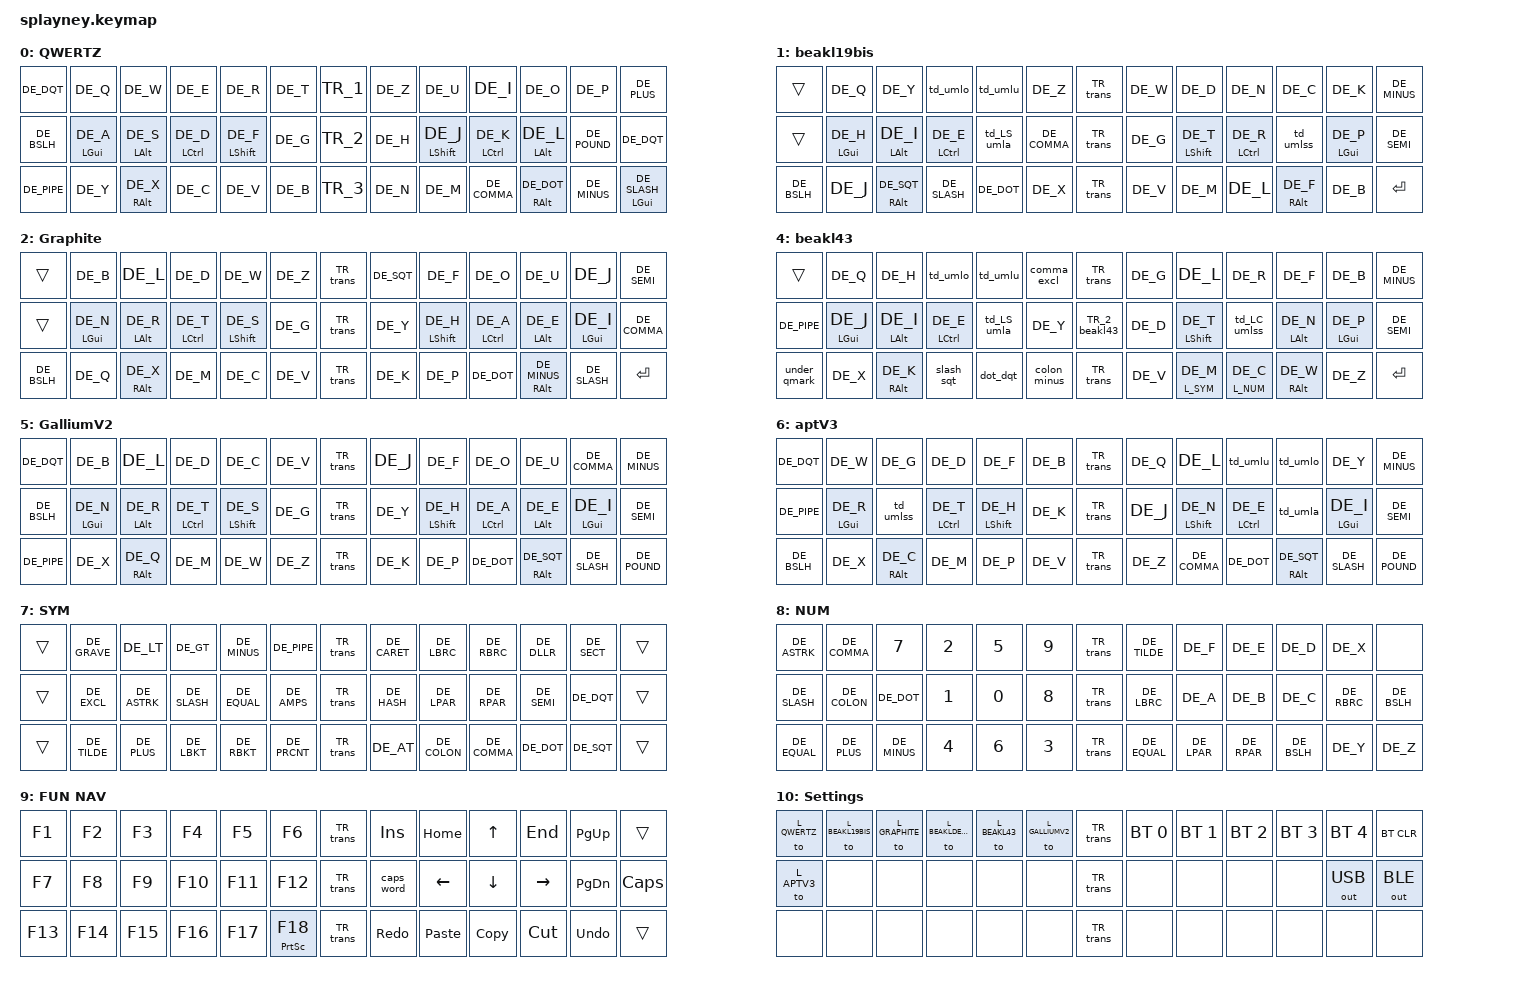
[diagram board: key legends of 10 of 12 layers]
/*
 * Copyright (c) 2023 The ZMK Contributors
 *
 * SPDX-License-Identifier: MIT
 */

#include <behaviors.dtsi>
#include <dt-bindings/zmk/bt.h>
#include <dt-bindings/zmk/keys.h>
#include <dt-bindings/zmk/outputs.h>

#define ZMK_POINTING_DEFAULT_MOVE_VAL 1500  // default: 600
#define ZMK_POINTING_DEFAULT_SCRL_VAL 100    // default: 10
#include <dt-bindings/zmk/pointing.h>

#include <locale/keys_de.h>
#include <locale/keys_us_international.h>

#define L_QWERTZ 0
#define L_BEAKL19BIS 1
#define L_GRAPHITE 2
#define L_BEAKLDETECH 3
#define L_BEAKL43 4
#define L_GALLIUMV2 5
#define L_APTV3 6

#define L_SYM 7
#define L_NUM 8
#define L_FUNNAV 9
#define L_SETTINGS 10
#define L_MEDIAMAUS 11

#define Undo   LC(Z)
#define Cut    LC(X)
#define Copy   LC(C)
#define Paste  LC(V)
#define Redo   LC(Y)

#include "combos.dtsi"

/*
            7.2 7.3     8.3 8.2
 6.1 6.2 6.3 7.1             8.1 9.3 9.2 9.1
*/

/*              Col 6                   7                         8                         9       */
#define TR_1    &lt L_NUM ESC           &lt L_MEDIAMAUS ENTER     &lt L_MEDIAMAUS ENTER     &lt L_NUM ESC  
#define TR_2    &lt L_SYM BSPC          &none                     &none                     &lt L_SYM DELETE
#define TR_3    &lt L_FUNNAV DE_SPACE   &mo L_SETTINGS            &mo L_SETTINGS            &lt L_FUNNAV DE_SPACE

#define TR_2_beakl43    &lt L_SYM BSPC          &bslh_pipe             &none                     &lt L_SYM DELETE

/*   │ SYM │ BSPC│SPACE│ENTER│   │ENTER│SPACE│DEL  │ NAV │ */
/*               Col 6          7                8               9       */
/*#define TR_B1    &mo L_SYM      &kp ENTER        &kp ENTER       &mo L_NUM   
#define TR_B2    &kp BSPC       &blsh_pipe       &none           &kp DELETE
#define TR_B3    &kp DE_SPACE   &mo L_SETTINGS   &mo L_SETTINGS  &kp DE_SPACE
*/
// #define TR_20   &lt L_SYMNUM DE_ESC    &none                     &mo L_NAV         &lt L_FUN DELETE 


#define TR_trans &trans &trans &trans &trans
#define TR_half_trans &trans &trans 


/*
#define TR_1 &kp DE_A &kp DE_B &kp DE_C &kp DE_D
#define TR_2 &kp DE_E &kp DE_F &kp DE_G &kp DE_H
#define TR_3 &kp DE_I &kp DE_J &kp DE_K &kp DE_L
*/


&mmv {
    acceleration-exponent = <1>;          // 1
    time-to-max-speed-ms = <1500>;         // 300
    delay-ms = <0>;                       // 0
};

&msc {
    acceleration-exponent = <0>;          // 0
    time-to-max-speed-ms = <5000>;         // 300
    delay-ms = <0>;                       // 0
};



/ {
    behaviors {

/* HOME ROW MODS */
        thm: homerow_mods {
            compatible = "zmk,behavior-hold-tap";
            #binding-cells = <2>;
            tapping-term-ms = <150>;
            quick-tap-ms = <0>;
            flavor = "tap-preferred";
            bindings = <&kp>, <&kp>;
        }; 
        hm: balanced_homerow_mods {
            compatible = "zmk,behavior-hold-tap";
            #binding-cells = <2>;
            tapping-term-ms = <400>;    // <---[[moderate duration]]
            quick-tap-ms = <0>;
            flavor = "tap-preferred";
            bindings = <&kp>, <&kp>;
        };

        // Ctrl, GUI (sehr bewusst)
        hm_strict: hmr_strict {
            compatible = "zmk,behavior-hold-tap";
            #binding-cells = <2>;
            flavor = "tap-preferred";
            tapping-term-ms = <260>;
            require-prior-idle-ms = <170>;
            quick-tap-ms = <120>;
            hold-trigger-on-release;
            bindings = <&kp>, <&kp>;
        };

        // Alt / RAlt (mittel)
        hm_mid: hmr_mid {
            compatible = "zmk,behavior-hold-tap";
            #binding-cells = <2>;
            flavor = "tap-preferred";
            tapping-term-ms = <240>;
            require-prior-idle-ms = <140>;
            quick-tap-ms = <120>;
            hold-trigger-on-release;
            bindings = <&kp>, <&kp>;
        };

        // Shift (am schnellsten)
        hm_shift: hmr_shift {
            compatible = "zmk,behavior-hold-tap";
            #binding-cells = <2>;
            flavor = "tap-preferred";
            tapping-term-ms = <210>;
            require-prior-idle-ms = <120>;
            quick-tap-ms = <110>;
            bindings = <&kp>, <&kp>;
         };
//            hold-trigger-on-release;


/*---------------------*/
     /*       
        mac_caps: mac_caps {
          compatible = "zmk,behavior-macro";
          #binding-cells = <0>;
          tap-ms = <100>;
          bindings = <&kp CAPS>;
        };
            
        tab_caps: tab_caps {
          compatible = "zmk,behavior-hold-tap";
          label = "TAB_CAPS";
          #binding-cells = <0>;
          tapping-term-ms = <200>;
          flavor = "tap-preferred";
          bindings = <&mac_caps>, <&kp TAB>;
        };
     */

        td_umla: tap_dance_generic_a {
            compatible = "zmk,behavior-tap-dance";
            #binding-cells = <0>;
            tapping-term-ms = <200>;
            bindings = <&mt LALT DE_A>, <&kp DE_A_UMLAUT>;
        };
/*
        td_LS_umla: tap_dance_generic_LS_a {
            compatible = "zmk,behavior-tap-dance";
            #binding-cells = <0>;
            tapping-term-ms = <200>;
            bindings = <&mt LSHIFT DE_A>, <&kp DE_A_UMLAUT>;
        };
*/
        td_LS_umla: tap_dance_generic_LS_a {
            compatible = "zmk,behavior-tap-dance";
            #binding-cells = <0>;
            tapping-term-ms = <210>;             // wie hm_shift
            // quick-tap-ms = <110>;                // schützt Doppeltaps
            // flavor = "tap-preferred";            // Tap first
            // hold-trigger-on-release;             // Hold wird erst beim Loslassen entschieden
            bindings = <&mt LSHIFT DE_A>, <&kp DE_A_UMLAUT>;
        };

        td_umlo: tap_dance_generic_o {
            compatible = "zmk,behavior-tap-dance";
            #binding-cells = <0>;
            tapping-term-ms = <200>;
            bindings = <&kp DE_O>, <&kp DE_O_UMLAUT>;
        };
        td_umlu: tap_dance_generic_u {
            compatible = "zmk,behavior-tap-dance";
            #binding-cells = <0>;
            tapping-term-ms = <200>;
            bindings = <&kp DE_U>, <&kp DE_U_UMLAUT>;
        };
        td_umlss: tap_dance_generic_LC_ss {
            compatible = "zmk,behavior-tap-dance";
            #binding-cells = <0>;
            tapping-term-ms = <200>;
            bindings = <&mt LALT DE_S>, <&kp DE_SHARP_S>;
        };
/*
        td_LC_umlss: tap_dance_generic_ss {
            compatible = "zmk,behavior-tap-dance";
            #binding-cells = <0>;
            tapping-term-ms = <200>;
            bindings = <&mt LCTRL DE_S>, <&kp DE_SHARP_S>;
        };
*/
        td_LC_umlss: tap_dance_generic_ss {
            compatible = "zmk,behavior-tap-dance";
            #binding-cells = <0>;
            // tapping-term-ms = <260>;          // wie hm_strict für Ctrl
            // quick-tap-ms = <120>;             // schützt Doppeltaps
            // flavor = "tap-preferred";         // Tap first
            // hold-trigger-on-release;          // Hold wird erst beim Loslassen entschieden
            bindings = <&mt LCTRL DE_S>, <&kp DE_SHARP_S>;
         };

        // BEAKL43
        comma_excl: comma_excl {
            compatible = "zmk,behavior-mod-morph";
            #binding-cells = <0>;
            // Das erste Binding ist für den unmodifizierten Zustand (ohne Shift)
            // Das zweite Binding ist für den modifizierten Zustand (mit Shift)
            bindings = <&kp DE_COMMA>, <&kp DE_EXCLAMATION>; 
            // Die Modifikatoren, die das Verhalten ändern sollen (linker oder rechter Shift)
            mods = <(MOD_LSFT | MOD_RSFT)>; 
        };
        quote_under: quote_under {
            compatible = "zmk,behavior-mod-morph";
            #binding-cells = <0>;
            bindings = <&kp DE_DQT>, <&kp DE_UNDERSCORE>;
            mods = <(MOD_LSFT | MOD_RSFT)>;
        };
        dot_grave: dot_grave {
            compatible = "zmk,behavior-mod-morph";
            #binding-cells = <0>;
            bindings = <&kp DE_DOT>, <&kp DE_GRAVE>;
            mods = <(MOD_LSFT | MOD_RSFT)>;
        };
        sq_qmark: sq_qmark {
            compatible = "zmk,behavior-mod-morph";
            #binding-cells = <0>;
            bindings = <&kp DE_SQT>, <&kp DE_QMARK>;
            mods = <(MOD_LSFT | MOD_RSFT)>;
        };
        slash_sqt: slash_sqt {
            compatible = "zmk,behavior-mod-morph";
            #binding-cells = <0>;
            bindings = <&kp DE_SLASH>, <&kp DE_SQT>;
            mods = <(MOD_LSFT | MOD_RSFT)>;
        };
        dot_dqt: dot_dqt {
            compatible = "zmk,behavior-mod-morph";
            #binding-cells = <0>;
            bindings = <&kp DE_DOT>, <&kp DE_DQT>;
            mods = <(MOD_LSFT | MOD_RSFT)>;
        };
        colon_minus: colon_minus {
            compatible = "zmk,behavior-mod-morph";
            #binding-cells = <0>;
            bindings = <&kp DE_COLON>, <&kp DE_MINUS>;
            mods = <(MOD_LSFT | MOD_RSFT)>;
            keep-mods = <0>;
        };
        bslh_pipe: bslh_pipe {
            compatible = "zmk,behavior-mod-morph";
            #binding-cells = <0>;
            bindings = <&kp DE_BSLH>, <&kp DE_PIPE>;
            mods = <(MOD_LSFT | MOD_RSFT)>;
        };
        under_qmark: under_qmark {
            compatible = "zmk,behavior-mod-morph";
            #binding-cells = <0>;
            bindings = <&kp DE_UNDER>, <&kp DE_QMARK>;
            mods = <(MOD_LSFT | MOD_RSFT)>;
        };

        semicolon_backtick: semicolon_backtick {
            compatible = "zmk,behavior-mod-morph";
            #binding-cells = <0>;
            // Normal: ; , Shift: `
            bindings = <&kp DE_SEMI>, <&kp DE_GRAVE>; 
            mods = <(MOD_LSFT | MOD_RSFT)>; 
        };

        hash_tilde: hash_tilde {
            compatible = "zmk,behavior-mod-morph";
            #binding-cells = <0>;
            // Normal: # , Shift: ~
            bindings = <&kp DE_HASH>, <&kp DE_TILDE>; 
            mods = <(MOD_LSFT | MOD_RSFT)>; 
        };

        equal_caret: equal_caret {
            compatible = "zmk,behavior-mod-morph";
            #binding-cells = <0>;
            // Normal: = , Shift: ^
            bindings = <&kp DE_EQUAL>, <&kp DE_CARET>; 
            mods = <(MOD_LSFT | MOD_RSFT)>; 
        };

        asterisk_plus: asterisk_plus {
            compatible = "zmk,behavior-mod-morph";
            #binding-cells = <0>;
            // Normal: * , Shift: +
            bindings = <&kp DE_ASTRK>, <&kp DE_PLUS>; 
            mods = <(MOD_LSFT | MOD_RSFT)>; 
        };


        // layer_quote_under: layer_quote_under {
        //     compatible = "zmk,behavior-hold-tap";
        //     // #binding-cells = <3>; // Tap-Binding und Hold-Binding
        //     tapping-term-ms = <400>; // Nutzt den gleichen tapping-term wie hm
        //     quick-tap-ms = <0>;
        //     flavor = "tap-preferred"; // Bevorzugt Tap, wie deine anderen HRMs
        //     // Binding 1 (Tap): Dein bestehendes mod-morph Behavior
        //     // Binding 2 (Hold): Layer-Wechsel zur gewünschten Symbol-Layer (hier ein Platzhalter, z.B. SYMBOL_LAYER)
        //     bindings = <&quote_under &mo 7>; // L_SYM Hier ist das erste Binding dein mod-morph
        // };

        // layer_dot_grave: layer_dot_grave {
        //     compatible = "zmk,behavior-hold-tap";
        //     // #binding-cells = <3>; // Tap-Binding und Hold-Binding
        //     tapping-term-ms = <400>; // Nutzt den gleichen tapping-term wie hm
        //     quick-tap-ms = <0>;
        //     flavor = "tap-preferred"; // Bevorzugt Tap, wie deine anderen HRMs
        //     // Binding 1 (Tap): Dein bestehendes mod-morph Behavior
        //     // Binding 2 (Hold): Layer-Wechsel zur gewünschten Numpad-Layer (hier ein Platzhalter, z.B. NUMPAD_LAYER)
        //     bindings = <&dot_grave &mo 8>; // L_NUM Hier ist das erste Binding dein mod-morph
        // };
    };

    keymap {
        compatible = "zmk,keymap";

        default_layer {
            bindings = <
                &kp DE_DQT   &kp DE_Q      &kp DE_W       &kp DE_E        &kp DE_R         &kp DE_T      TR_1    &kp DE_Z  &kp DE_U        &kp DE_I          &kp DE_O        &kp DE_P           &kp DE_PLUS
                &kp DE_BSLH  &hm LGUI DE_A &hm LALT DE_S  &hm LCTRL DE_D  &hm LSHIFT DE_F  &kp DE_G      TR_2    &kp DE_H  &hm LSHIFT DE_J &hm LCTRL DE_K    &hm LALT DE_L   &kp DE_POUND       &kp DE_DQT
                &kp DE_PIPE  &kp DE_Y      &hm RALT DE_X  &kp DE_C        &kp DE_V         &kp DE_B      TR_3    &kp DE_N  &kp DE_M        &kp DE_COMMA      &hm RALT DE_DOT &kp DE_MINUS       &hm LGUI DE_SLASH
            >;
            label = "QWERTZ";
        };

        // beakl19bis
        layer_beakl19bis {
            bindings = <    
                &trans      &kp DE_Q      &kp DE_Y         &td_umlo        &td_umlu         &kp DE_Z      TR_trans         &kp DE_W  &kp DE_D          &kp DE_N        &kp DE_C          &kp DE_K       &kp DE_MINUS
                &trans      &hm LGUI DE_H &hm LALT DE_I    &hm LCTRL DE_E  &td_LS_umla      &kp DE_COMMA  TR_trans         &kp DE_G  &hm LSHIFT  DE_T  &hm LCTRL DE_R  &td_umlss         &hm LGUI DE_P  &kp DE_SEMI
                &kp DE_BSLH &kp DE_J      &hm RALT DE_SQT  &kp DE_SLASH    &kp DE_DOT       &kp DE_X      TR_trans         &kp DE_V  &kp DE_M          &kp DE_L        &hm RALT DE_F     &kp DE_B       &kp ENTER
            >;
            label = "beakl19bis";
        };

        // GRAPHITE
        layer_graphite {
            bindings = <
                &trans       &kp DE_B       &kp DE_L       &kp DE_D        &kp DE_W         &kp DE_Z   TR_trans    &kp DE_SQT  &kp DE_F         &kp DE_O         &kp DE_U           &kp DE_J       &kp DE_SEMI
                &trans       &hm LGUI DE_N  &hm LALT DE_R  &hm LCTRL DE_T  &hm LSHIFT DE_S  &kp DE_G   TR_trans    &kp DE_Y    &hm LSHIFT DE_H  &hm LCTRL DE_A   &hm LALT DE_E      &hm LGUI DE_I  &kp DE_COMMA
                &kp DE_BSLH  &kp DE_Q       &hm RALT DE_X  &kp DE_M        &kp DE_C         &kp DE_V   TR_trans    &kp DE_K    &kp DE_P         &kp DE_DOT       &hm RALT DE_MINUS  &kp DE_SLASH   &kp ENTER
            >;
            label = "Graphite";
        };

            /*  1            2             3                4                   5                 6           |TL 7            8           TR 9              10             | 11        12               13              14                15             16           */

        layer_beakldetech {
            bindings = <
                &kp ESC      &kp DE_J             &kp DE_H             &td_umlo               &td_umlu          &comma_excl     &lt L_FUNNAV DE_LT  &kp ENTER      &kp ENTER           &asterisk_plus   &kp DE_G  &kp DE_L               &kp DE_R        &kp DE_F          &kp DE_B       &hash_tilde
                &mt CAPS TAB &hm_strict LGUI DE_Q &hm_mid LALT DE_I    &hm_strict LCTRL DE_E  &td_LS_umla       &kp DE_Z        &kp BSPC            &bslh_pipe     &under_qmark        &kp DELETE       &kp DE_D  &hm_shift LSHIFT DE_T  &td_LC_umlss    &hm_mid LALT DE_N     &hm_strict LGUI DE_P  &equal_caret
                &mo L_SYM    &kp DE_X             &hm_mid RALT DE_K    &slash_sqt             &dot_dqt          &colon_minus    &kp DE_SPACE        &mo L_SETTINGS &semicolon_backtick &kp DE_SPACE     &kp DE_V  &kp DE_M               &kp DE_C        &hm RALT DE_W     &kp DE_Y       &mo L_NUM
            >;
            label = "BEAKL-DETECH"; 
        };


        // BEAKL 43

        // kb-beakl-numpad-full
        // tab + / * =        y x z
        // -   5 2 3 :      ~ F E D   
        // 7   . 1 0 4      { C B A }
        // ,   6 9 8 entr     ( ) \

        // kb-beakl-numpad-full shift layer
        // tab @ $ # %        Y X Z
        // !   ! [ ] =      _ f e d   
        // &   $ # % |        c b a 
        // ;   < ^ > 8 entr     ( ) \


        // kb-beakl-numpad-5
        // tab * / 4 =        y x Z
        // ,   7 2 5 9      ~ F E D   
        // :   . 1 0 8      { C B A }
        // +   -   6 3        ( ) \        
        // kb-beakl-numpad-5 shift layer
        // tab @ $ # %        Y X Z
        // !   ! [ ] =      _ f e d   
        // &   $ # % |        a b c 
        // ;   <   > ^        ( ) \

        // kb-beakl-puncs
        // k r m z          z m r k
        //   @ $ #            ^ 
        //   < = >          [ _ ]   
        // \ ( - ) +      % { ; } !
        //   * : /          | ~ &

        // BEAKL 43 (main layer):
        //   32104 76598
        //   qhou, glrfb
        //   jieay dtsnp
        //   xk".' vmcwz
        //   xk/.:  \ vmcwz

        // BEAKL 43 (shift layer):
        //   |@$#% ^(~)&
        //   QHOU! GLRFB
        //   JIEAY DTSNP
        //   XK_`? VMCWZ
        //   XK'"- VMCWZ

        layer_beakl43 {
            bindings = <    
                &trans       &kp DE_Q      &kp DE_H         &td_umlo            &td_umlu          &comma_excl   TR_trans         &kp DE_G  &kp DE_L         &kp DE_R        &kp DE_F          &kp DE_B       &kp DE_MINUS
                &kp DE_PIPE  &hm LGUI DE_J &hm LALT DE_I    &hm LCTRL DE_E      &td_LS_umla       &kp DE_Y      TR_2_beakl43     &kp DE_D  &hm LSHIFT DE_T  &td_LC_umlss    &hm LALT DE_N     &hm LGUI DE_P  &kp DE_SEMI
                &under_qmark &kp DE_X      &hm RALT DE_K    &slash_sqt          &dot_dqt          &colon_minus  TR_trans         &kp DE_V  &hm L_SYM  DE_M  &hm L_NUM DE_C  &hm RALT DE_W     &kp DE_Z       &kp ENTER
            >;
            label = "beakl43";
        };

        // layer_colemak {
        //     bindings = <
        //         &trans  &kp DE_Q      &kp DE_W       &kp DE_F        &kp DE_P         &kp DE_B   TR_trans    &kp DE_J  &kp DE_L         &kp DE_U        &kp DE_Y         &kp DE_SEMICOLON &trans
        //         &trans  &hm LGUI DE_A &hm LALT DE_R  &hm LCTRL DE_S  &hm LSHIFT DE_T  &kp DE_G   TR_trans    &kp DE_M  &hm LSHIFT DE_N  &hm LCTRL DE_E  &hm LALT DE_I    &hm LGUI DE_O    &trans
        //         &trans  &kp DE_Z      &hm RALT DE_X  &kp DE_C        &kp DE_D         &kp DE_V   TR_trans    &kp DE_K  &kp DE_H         &kp DE_COMMA    &hm RALT DE_DOT  &kp DE_SLASH     &trans
        //     >;
        //     label = "ColemakDH";   
        // };


        layer_galliumv2 {
            bindings = <
                &kp DE_DQT   &kp DE_B      &kp DE_L       &kp DE_D        &kp DE_C         &kp DE_V     TR_trans    &kp DE_J  &kp DE_F         &kp DE_O        &kp DE_U          &kp DE_COMMA   &kp DE_MINUS
                &kp DE_BSLH  &hm LGUI DE_N &hm LALT DE_R  &hm LCTRL DE_T  &hm LSHIFT DE_S  &kp DE_G     TR_trans    &kp DE_Y  &hm LSHIFT DE_H  &hm LCTRL DE_A  &hm LALT DE_E     &hm LGUI DE_I  &kp DE_SEMI
                &kp DE_PIPE  &kp DE_X      &hm RALT DE_Q  &kp DE_M        &kp DE_W         &kp DE_Z     TR_trans    &kp DE_K  &kp DE_P         &kp DE_DOT      &hm RALT DE_SQT   &kp DE_SLASH   &kp DE_POUND
            >;
            label = "GalliumV2";   
        };

        layer_aptV3 {
            bindings = <
                &kp DE_DQT   &kp DE_W      &kp DE_G       &kp DE_D        &kp DE_F         &kp DE_B     TR_trans    &kp DE_Q  &kp DE_L         &td_umlu        &td_umlo          &kp DE_Y       &kp DE_MINUS
                &kp DE_PIPE  &hm LGUI DE_R &td_umlss      &hm LCTRL DE_T  &hm LSHIFT DE_H  &kp DE_K     TR_trans    &kp DE_J  &hm LSHIFT DE_N  &hm LCTRL DE_E  &td_umla          &hm LGUI DE_I  &kp DE_SEMI
                &kp DE_BSLH  &kp DE_X      &hm RALT DE_C  &kp DE_M        &kp DE_P         &kp DE_V     TR_trans    &kp DE_Z  &kp DE_COMMA     &kp DE_DOT      &hm RALT DE_SQT   &kp DE_SLASH   &kp DE_POUND
            >;
            label = "aptV3";   
        };  

        // _ ° & \ [ *     _ _ . _    [ 7 8 9 ] _
        // _ § < $ ( %     _ _ _ -    = 4 5 6 ; _
        // _ ~ @ ! { ?     _ _ _ 0    \ 1 2 3 ` _
        // layer_symnum {
        //     bindings = <    
        //         &trans   &kp DE_DEG   &kp DE_AMPS &kp DE_BSLH  &kp DE_LBKT  &kp DE_ASTRK     TR_half_trans  &kp DE_DOT  &trans           &kp DE_LBKT  &kp N7 &kp N8 &kp N9 &kp DE_RBKT  &trans
        //         &trans   &kp DE_SECT  &kp DE_LT   &kp DE_DLLR  &kp DE_LPAR  &kp DE_PRCNT     TR_half_trans  &trans      &kp DE_MINUS     &kp DE_EQUAL &kp N4 &kp N5 &kp N6 &kp DE_SEMI  &trans
        //         &trans   &kp DE_TILDE &kp DE_AT   &kp DE_EXCL  &kp DE_LBRC  &kp DE_QMARK     TR_half_trans  &trans      &kp N0           &kp DE_BSLH  &kp N1 &kp N2 &kp N3 &kp DE_GRAVE &trans
        //     >;
        //     label = "SYM NUM";
        // };


        // kb-beakl-puncs
        //   k r m z          z m r k
        // _   @ $ #            ^ 
        // _   < = >          [ _ ]   
        // _ \ ( - ) +      % { ; } !
        // _   * : /          | ~ &

        // https://getreuer.info/posts/keyboards/symbol-layer/index.html
        // _ ` < > - |    _ _ _ _    ^ { } $ § _
        // _ ! * / = &    _ _ _ _    # ( ) ; " _
        // _ ~ + [ ] %    _ _ _ _    @ : , . ' _

        layer_sym {
            bindings = <    
                &trans   &kp DE_GRAVE &kp DE_LT    &kp DE_GT    &kp DE_MINUS &kp DE_PIPE      TR_trans        &kp DE_CARET &kp DE_LBRC  &kp DE_RBRC  &kp DE_DLLR &kp DE_SECT  &trans
                &trans   &kp DE_EXCL  &kp DE_ASTRK &kp DE_SLASH &kp DE_EQUAL &kp DE_AMPS      TR_trans        &kp DE_HASH  &kp DE_LPAR  &kp DE_RPAR  &kp DE_SEMI &kp DE_DQT   &trans
                &trans   &kp DE_TILDE &kp DE_PLUS  &kp DE_LBKT  &kp DE_RBKT  &kp DE_PRCNT     TR_trans        &kp DE_AT    &kp DE_COLON &kp DE_COMMA &kp DE_DOT  &kp DE_SQT   &trans
            >;
            label = "SYM";
        };

        // ---------------------------------------------------------------------
        // | * , 7 2 5 9 |   | ~ F E D x z |  <-- Obere Reihe
        // | / : . 1 0 8 |   | { C B A } \ |  <-- Mittlere Reihe (Home Row)
        // | = + - 4 6 3 |   | = ( ) \ y   |  <-- Untere Reihe
        layer_num {
            bindings = <    
                &kp DE_ASTRK &kp DE_COMMA &kp N7       &kp N2 &kp N5 &kp N9       TR_trans       &kp DE_TILDE &kp DE_F    &kp DE_E    &kp DE_D    &kp DE_X    &none
                &kp DE_SLASH &kp DE_COLON &kp DE_DOT   &kp N1 &kp N0 &kp N8       TR_trans       &kp DE_LBRC  &kp DE_A    &kp DE_B    &kp DE_C    &kp DE_RBRC &kp DE_BSLH
                &kp DE_EQUAL &kp DE_PLUS  &kp DE_MINUS &kp N4 &kp N6 &kp N3       TR_trans       &kp DE_EQUAL &kp DE_LPAR &kp DE_RPAR &kp DE_BSLH &kp DE_Y    &kp DE_Z
            >;
            label = "NUM";
        };

/*         layer_symnum {
            bindings = <    
                &trans   &kp DE_DEG   &kp DE_AMPS &kp DE_BSLH  &kp DE_LBKT  &kp DE_ASTRK     TR_half_trans  &kp DE_DOT  &trans           &kp DE_LBKT  &kp N7 &kp N8 &kp N9 &kp DE_RBKT  &trans
                &trans   &kp DE_SECT  &kp DE_LT   &kp DE_DLLR  &kp DE_LPAR  &kp DE_PRCNT     TR_half_trans  &trans      &kp DE_MINUS     &kp DE_EQUAL &kp N4 &kp N5 &kp N6 &kp DE_SEMI  &trans
                &trans   &kp DE_TILDE &kp DE_AT   &kp DE_EXCL  &kp DE_LBRC  &kp DE_QMARK     TR_half_trans  &trans      &kp N0           &kp DE_BSLH  &kp N1 &kp N2 &kp N3 &kp DE_GRAVE &trans
            >;
            label = "SYMNUM";
        };
 */        
        layer_funnav { 
            bindings = <
                &kp F1  &kp F2  &kp F3  &kp F4  &kp F5   &kp F6          TR_trans       &kp INS      &kp HOME  &kp UP    &kp END    &kp PG_UP    &trans
                &kp F7  &kp F8  &kp F9  &kp F10 &kp F11  &kp F12         TR_trans       &caps_word   &kp LEFT  &kp DOWN  &kp RIGHT  &kp PG_DN    &kp CAPS
                &kp F13 &kp F14 &kp F15 &kp F16 &kp F17  &hm PSCRN F18   TR_trans       &kp Redo     &kp Paste &kp Copy  &kp Cut    &kp Undo     &trans
            >;
            label = "FUN NAV";
        };

        layer_settings {
            bindings = <
                &to L_QWERTZ &to L_BEAKL19BIS  &to L_GRAPHITE &to L_BEAKLDETECH &to L_BEAKL43 &to L_GALLIUMV2      TR_trans     &bt BT_SEL 0 &bt BT_SEL 1 &bt BT_SEL 2 &bt BT_SEL 3 &bt BT_SEL 4 &bt BT_CLR 
                &to L_APTV3  &none             &none          &none             &none         &none                TR_trans     &none        &none        &none        &none        &out OUT_USB &out OUT_BLE
                &none        &none             &none          &none             &none         &none                TR_trans     &none        &none        &none        &none        &none        &none
            >; 
            label = "Settings";
        };
        layer_mediamaus {
            bindings = <
                &trans &none    &none    &kp C_VOL_DN       &kp C_VOL_UP        &kp C_MUTE      TR_half_trans    &mkp LCLK  &none      &msc SCRL_UP   &msc SCRL_LEFT &mmv MOVE_UP   &msc SCRL_RIGHT &none     &trans
                &trans &kp LGUI &kp LALT &hm LCTRL C_BRI_DN &hm LSHIFT C_BRI_UP &kp C_BRI_MIN   TR_half_trans    &none      &mkp RCLK  &msc SCRL_DOWN &mmv MOVE_LEFT &mmv MOVE_DOWN &mmv MOVE_RIGHT &none     &trans
                &trans &none    &kp RALT &none              &none               &none           TR_half_trans    &none      &mkp MCLK  &kp Redo       &kp Paste      &kp Copy       &kp Cut         &kp Undo  &trans
            >;
            label = "Media+Maus";
        };
    };
};

                                                
                
